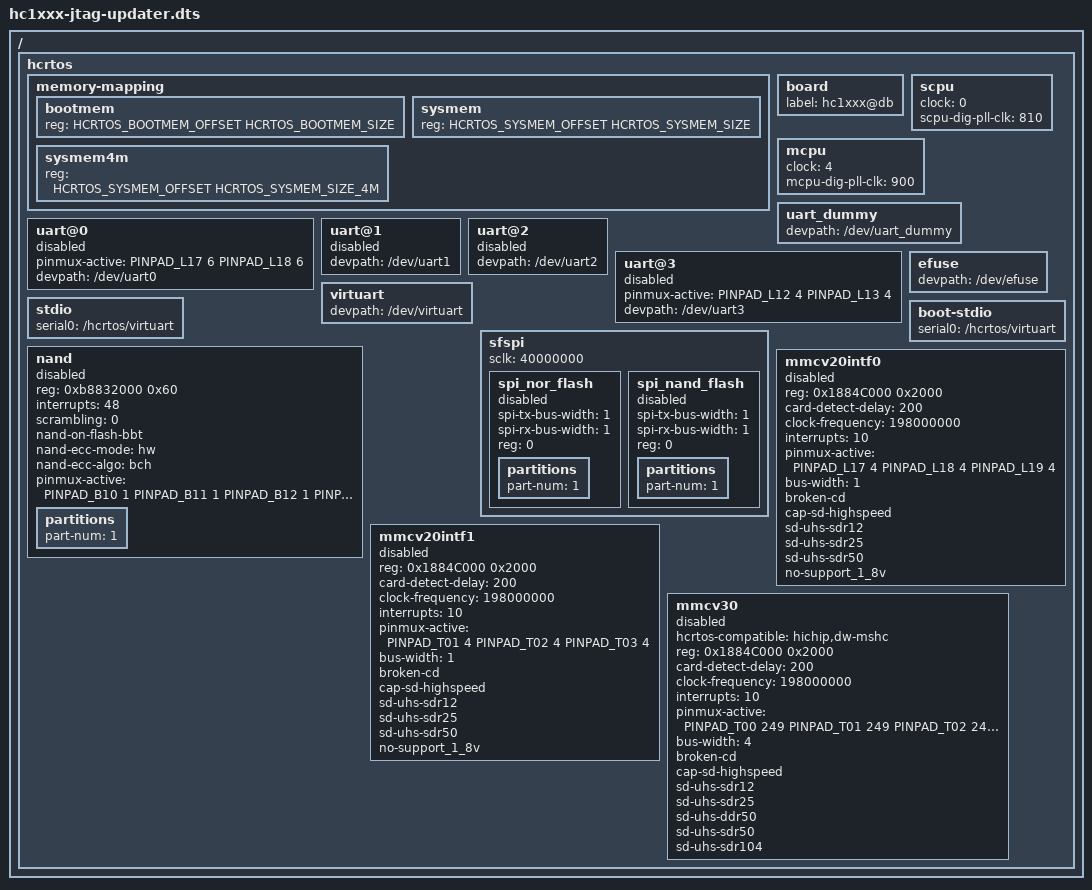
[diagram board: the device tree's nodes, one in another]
/dts-v1/;

#include <dt-bindings/gpio/gpio.h>
#include <uapi/hcuapi/pinpad.h>

#define CONFIG_MEMORY_SIZE 0x01000000
#define CONFIG_MEMORY_SIZE_4M 0x00400000

#define HCRTOS_SYSMEM_OFFSET (0)
#define HCRTOS_SYSMEM_SIZE (CONFIG_MEMORY_SIZE)
#define HCRTOS_SYSMEM_SIZE_4M (CONFIG_MEMORY_SIZE_4M)

#define HCRTOS_BOOTMEM_OFFSET (0)
#define HCRTOS_BOOTMEM_SIZE (CONFIG_MEMORY_SIZE)
#define HCRTOS_BOOTMEM_SIZE_4M (CONFIG_MEMORY_SIZE_4M)

/{
hcrtos {
	#address-cells = <1>;
	#size-cells = <1>;
	memory-mapping {
		#address-cells = <1>;
		#size-cells = <1>;
		bootmem {
			reg = <HCRTOS_BOOTMEM_OFFSET HCRTOS_BOOTMEM_SIZE>;
		};

		sysmem {
			reg = <HCRTOS_SYSMEM_OFFSET HCRTOS_SYSMEM_SIZE>;
		};

		sysmem4m {
			reg = <HCRTOS_SYSMEM_OFFSET HCRTOS_SYSMEM_SIZE_4M>;
		};
	};

	board {
		label = "hc1xxx@db";
	};

	scpu {
		/*
		 * 0 : 594M
		 * 1 : 396M
		 * 2 : 297M
		 * 3 : 198M
		 * 4 : 198M
		 * 5 : 198M
		 * 6 : 198M
		 * 7 : SCPU dig pll clk
		 */
		clock = <0>;
		scpu-dig-pll-clk = <810>;
	};

	mcpu {
		/*
		 * 0 : 594M
		 * 1 : 396M
		 * 2 : 297M
		 * 3 : 198M
		 * 4 : 900M
		 * 5 : 1188M
		 * 6 : 24M
		 * 7 : CPU dig pll clk
		 */
		clock = <4>;
		mcpu-dig-pll-clk = <900>;
	};

	uart_dummy {
		devpath = "/dev/uart_dummy";
		status = "okay";
	};

	uart@0 {
		pinmux-active = <PINPAD_L17 6 PINPAD_L18 6>;
		devpath = "/dev/uart0";
		status = "disabled";
	};

	uart@1 {
		devpath = "/dev/uart1";
		status = "disabled";
	};

	uart@2 {
		devpath = "/dev/uart2";
		status = "disabled";
	};

	uart@3 {
		pinmux-active = <PINPAD_L12 4 PINPAD_L13 4>;
		devpath = "/dev/uart3";
		status = "disabled";
	};

	efuse {
		devpath = "/dev/efuse";
		status = "okay";
	};

	virtuart {
		devpath = "/dev/virtuart";
		status = "okay";
	};

	stdio {
		serial0 = "/hcrtos/virtuart";
	};

	boot-stdio {
		serial0 = "/hcrtos/virtuart";
	};

	sfspi {
		sclk = <40000000>;
		status = "okay";

		spi_nor_flash {
			spi-tx-bus-width = <1>;
			spi-rx-bus-width = <1>;
			reg = <0>;
			status = "disabled";
			partitions {
				part-num = <1>;
				/* part0 is for entire norflash by default */
			};
		};

		spi_nand_flash {
			spi-tx-bus-width = <1>;
			spi-rx-bus-width = <1>;
			reg = <0>;
			status = "disabled";
			partitions {
				part-num = <1>;
				/* part0 is for entire norflash by default */
			};
		};
	};

	nand {
		reg = <0xb8832000 0x60>;
		interrupts = <48>;
		scrambling = <0>;
		nand-on-flash-bbt;
		nand-ecc-mode = "hw";
		nand-ecc-algo = "bch";

		pinmux-active = <PINPAD_B10 1 PINPAD_B11 1 PINPAD_B12 1 PINPAD_B13 1 PINPAD_B14 1
				PINPAD_B15 1 PINPAD_B16 1 PINPAD_B17 1 PINPAD_B18 1 PINPAD_B19 1
				PINPAD_B20 1 PINPAD_B21 1 PINPAD_B22 1 PINPAD_B23 1 PINPAD_B24 1>;

		status = "disabled";
		partitions {
			part-num = <1>;
			/* part0 is for entire nand by default */
		};
	};

	mmcv20intf0 {
		//hcrtos-compatible = "hichip,dw-mshc";
		// compatible = "snps,dw-mshc";
		reg = <0x1884C000 0x2000>;
		card-detect-delay = <200>;
		clock-frequency = <198000000>;
		interrupts = <10>;
		pinmux-active = <PINPAD_L17 4 PINPAD_L18 4 PINPAD_L19 4>;
		// bus-width = <8>;
		//bus-width = <4>;
		bus-width = <1>;
		broken-cd;
		//cd-gpios = <PINPAD_L15 1>;
		//non-removable;
	
		cap-sd-highspeed;
		sd-uhs-sdr12;
		sd-uhs-sdr25;
		sd-uhs-sdr50;
		no-support_1_8v;
		status = "disabled";
	};

	mmcv20intf1 {
		//hcrtos-compatible = "hichip,dw-mshc";
		// compatible = "snps,dw-mshc";
		reg = <0x1884C000 0x2000>;
		card-detect-delay = <200>;
		clock-frequency = <198000000>;
		interrupts = <10>;
		pinmux-active = <PINPAD_T01 4 PINPAD_T02 4 PINPAD_T03 4>;
		// bus-width = <8>;
		//bus-width = <4>;
		bus-width = <1>;
		broken-cd;
		//cd-gpios = <PINPAD_L15 1>;
		//non-removable;
	
		cap-sd-highspeed;
		sd-uhs-sdr12;
		sd-uhs-sdr25;
		sd-uhs-sdr50;
		no-support_1_8v;
		status = "disabled";
	};

	mmcv30 {
		hcrtos-compatible = "hichip,dw-mshc";
		// compatible = "snps,dw-mshc";
		reg = <0x1884C000 0x2000>;
		card-detect-delay = <200>;
		clock-frequency = <198000000>;
		//clocks = <&mmcclk>, <&mmcclk>;
		//clock-names = "biu", "ciu";
		interrupts = <10>;
		
		pinmux-active = <PINPAD_T00 249 PINPAD_T01 249 PINPAD_T02 249 PINPAD_T03 249 PINPAD_T04 249 PINPAD_T05 249>;
		
		status = "disabled";
		
		// bus-width = <8>;
		bus-width = <4>;
		// bus-width = <1>;
		
		broken-cd;
		//cd-gpios = <109 GPIO_ACTIVE_LOW>;
		//non-removable;
		
		cap-sd-highspeed;
		sd-uhs-sdr12;
		sd-uhs-sdr25;
		sd-uhs-ddr50;
		sd-uhs-sdr50;
		sd-uhs-sdr104;
	};
};
};
